# MB9AF31xL register map
File version: 1.8
CPU: 
Registers are 8-bit, read-write, reset 0x0 unless marked. A register's access mark holds for its fields unless they carry their own. Offsets are from the block's base; lines under a group give offsets from that group; [hi:lo] are bit positions; {n}, {i} and the like mark numbered series; 'fields as' and 'values as' point back to an identical list; <NAME> marks a mode.

## Memory map
0x40000000 FLASH_IF size 0xC — Flash Memory
0x40010000 CRG size 0x1 — Clock Unit Registers
0x40011000 HWWDT size 0x4 — Hardware Watchdog Timer
0x40012000 SWWDT size 0x4 — Software Watchdog Timer
0x40015000 DTIM size 0x1C — Dual Timer
0x40020000 MFT0 size 0x2 — Multifunction Timer 0
0x40021000 MFT1 size 0x2 — Multifunction Timer 0
0x40024000 MFT_PPG size 0x2 — PPG Configuration
0x40025000 BT0 size 0x2 — Base Timer 0
0x40025040 BT1 size 0x2 — Base Timer 0
0x40025080 BT2 size 0x2 — Base Timer 0
0x400250C0 BT3 size 0x2 — Base Timer 0
0x40025100 BTIOSEL03 size 0x2 — Base Timer I/O Select
0x40025200 BT4 size 0x2 — Base Timer 0
0x40025240 BT5 size 0x2 — Base Timer 0
0x40025280 BT6 size 0x2 — Base Timer 0
0x400252C0 BT7 size 0x2 — Base Timer 0
0x40025300 BTIOSEL47 size 0x2 — Base Timer I/O Select
0x40025F00 SBSSR blocks up to offset 0xFE — Software-based Simultaneous Startup Register
0x40026000 QPRC0 size 0x2 — Quadrature Position/Revolution Counter 0
0x40026040 QPRC1 size 0x2 — Quadrature Position/Revolution Counter 0
0x40027000 ADC0 size 0x2 — ADC0 Registers
0x40027100 ADC1 size 0x2 — ADC0 Registers
0x4002E000 CRTRIM size 0x1 — CR Trimming Registers
0x40030000 EXTI size 0x2 — External Interrupt and NMI Control
0x40031000 INTREQ size 0x4 — Interrupts
0x40033000 GPIO size 0x630 — General-purpose I/O ports
0x40035000 LVD size 0x1 — Low-voltage Detection
0x40036000 USBCLK size 0x1 — USB Clock
0x40038000 MFS0 size 0x2 — Multi-function Serial Interface 0
0x40038100 MFS1 size 0x2 — Multi-function Serial Interface 0
0x40038200 MFS2 size 0x2 — Multi-function Serial Interface 0
0x40038300 MFS3 size 0x2 — Multi-function Serial Interface 0
0x40038400 MFS4 size 0x2 — Multi-function Serial Interface 4
0x40038500 MFS5 size 0x2 — Multi-function Serial Interface 4
0x40038600 MFS6 size 0x2 — Multi-function Serial Interface 4
0x40038700 MFS7 size 0x2 — Multi-function Serial Interface 4
0x40039000 CRC size 0x1 — CRC Registers
0x4003A000 WC size 0x3 — Watch Counter
0x40040000 USB0 blocks up to offset 0x2102 — USB0 Function
0x40060000 DMAC size 0x4 — DMAC Registers

## Interrupts
0 CSV (CRG)
1 SWDT (SWWDT)
2 LVD
3 WFG (MFT0, MFT1)
4 EXTINT0_7 (EXTI)
5 EXTINT8_15 (EXTI)
6 DTIM_QDU (DTIM)
{2n+7} MFS{n}RX (MFS{n}) (n=0..7)
{2n+8} MFS{n}TX (MFS{n}) (n=0..7)
23 PPG (MFT_PPG)
24 OSC_PLL_WC (CRG)
25 ADC0
26 ADC1
28 FRTIM (MFT0, MFT1)
29 INCAP (MFT0, MFT1)
30 OUTCOMP (MFT0, MFT1)
31 BTIM0_7 (BT{n} (n=0..7))
34 USBF (USB0)
35 USBF_USBH (USB0)
{n+38} DMAC{n} (DMAC) (n=0..7)

## FLASH_IF — Flash Memory
Base 0x40000000
0x00 FASZR 32-bit reset 0x2 — Flash Access Size Register
  [1:0] ASZ — Flash Access Size
0x04 FRWTR 32-bit — Flash Read Wait Register
  [1:0] RWT — Read Wait Cycle
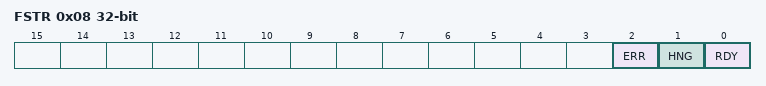
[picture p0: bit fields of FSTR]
0x08 FSTR 32-bit ro — Flash Status Register
  [2] ERR rw — Flash ECC Error
  [1] HNG — Flash Hang flag
  [0] RDY — Flash Rdy
0x10 FSYNDN 32-bit — Flash Sync Down Register
  [2:0] SD — Flash Sync
0x100 CRTRMM 32-bit ro reset not defined — CR Trimming Data Mirror Register
  [9:0] TRMM — CR Trimming Data Mirror

## CRTRIM — CR Trimming Registers
Base 0x4002E000
0x00 MCR_PSR reset 0x1 — High-speed CR oscillation Frequency Division Setup Register
  [1:0] CSR — High-speed CR oscillation frequency division ratio setting bits
0x04 MCR_FTRM 16-bit reset 0x7F — High-speed CR oscillation Frequency Trimming Register
  [7:0] TRD — Frequency trimming setup bits
0x0C MCR_RLR 32-bit reset 0x1 — High-Speed CR Oscillation Register Write-Protect Register
  [31:0] TRMLCK — Register write-protect bits

## SWWDT — Software Watchdog Timer
Base 0x40012000
0x00 WDOGLOAD 32-bit reset 0xFFFFFFFF — Software Watchdog Timer Load Register
0x04 WDOGVALUE 32-bit ro reset 0xFFFFFFFF — Software Watchdog Timer Value Register
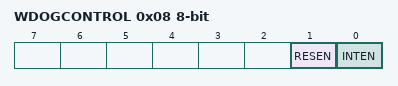
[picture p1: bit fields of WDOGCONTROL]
0x08 WDOGCONTROL — Software Watchdog Timer Control Register
  [1] RESEN — Reset enable bit of the software watchdog
  [0] INTEN — Interrupt and counter enable bit of the software watchdog
0x0C WDOGINTCLR 32-bit reset 0xFFFFFFFF — Software Watchdog Timer Clear Register
0x10 WDOGRIS ro — Software Watchdog Timer Interrupt Status Register
  [0] RIS — Software watchdog interrupt status bit
0xC00 WDOGLOCK 32-bit — Software Watchdog Timer Lock Register
